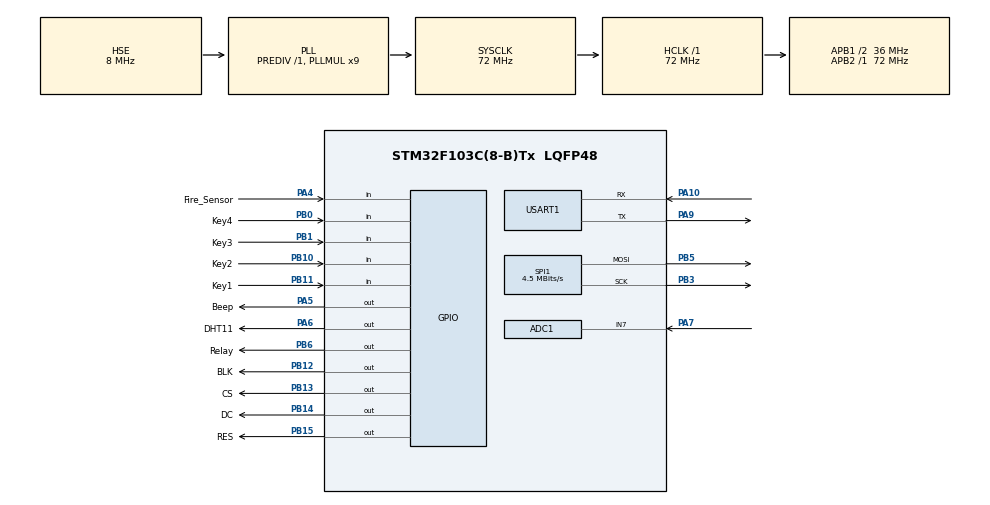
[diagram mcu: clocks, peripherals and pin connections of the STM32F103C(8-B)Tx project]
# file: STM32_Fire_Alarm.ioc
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ADC1.Channel-0\#ChannelRegularConversion=ADC_CHANNEL_7
ADC1.NbrOfConversionFlag=1
ADC1.Rank-0\#ChannelRegularConversion=1
ADC1.SamplingTime-0\#ChannelRegularConversion=ADC_SAMPLETIME_1CYCLE_5
ADC1.master=1
Dma.ADC1.3.Direction=DMA_PERIPH_TO_MEMORY
Dma.ADC1.3.Instance=DMA1_Channel1
Dma.ADC1.3.MemDataAlignment=DMA_MDATAALIGN_HALFWORD
Dma.ADC1.3.MemInc=DMA_MINC_ENABLE
Dma.ADC1.3.Mode=DMA_NORMAL
Dma.ADC1.3.PeriphDataAlignment=DMA_PDATAALIGN_HALFWORD
Dma.ADC1.3.PeriphInc=DMA_PINC_DISABLE
Dma.ADC1.3.Priority=DMA_PRIORITY_LOW
Dma.Request0=USART1_RX
Dma.Request1=USART1_TX
Dma.Request2=SPI1_TX
Dma.Request3=ADC1
Dma.SPI1_TX.2.Direction=DMA_MEMORY_TO_PERIPH
Dma.SPI1_TX.2.Instance=DMA1_Channel3
Dma.SPI1_TX.2.MemDataAlignment=DMA_MDATAALIGN_BYTE
Dma.SPI1_TX.2.MemInc=DMA_MINC_ENABLE
Dma.SPI1_TX.2.Mode=DMA_NORMAL
Dma.SPI1_TX.2.PeriphDataAlignment=DMA_PDATAALIGN_BYTE
Dma.SPI1_TX.2.PeriphInc=DMA_PINC_DISABLE
Dma.SPI1_TX.2.Priority=DMA_PRIORITY_LOW
Dma.USART1_RX.0.Direction=DMA_PERIPH_TO_MEMORY
Dma.USART1_RX.0.Instance=DMA1_Channel5
Dma.USART1_RX.0.MemDataAlignment=DMA_MDATAALIGN_BYTE
Dma.USART1_RX.0.MemInc=DMA_MINC_ENABLE
Dma.USART1_RX.0.Mode=DMA_NORMAL
Dma.USART1_RX.0.PeriphDataAlignment=DMA_PDATAALIGN_BYTE
Dma.USART1_RX.0.PeriphInc=DMA_PINC_DISABLE
Dma.USART1_RX.0.Priority=DMA_PRIORITY_LOW
Dma.USART1_TX.1.Direction=DMA_MEMORY_TO_PERIPH
Dma.USART1_TX.1.Instance=DMA1_Channel4
Dma.USART1_TX.1.MemDataAlignment=DMA_MDATAALIGN_BYTE
Dma.USART1_TX.1.MemInc=DMA_MINC_ENABLE
Dma.USART1_TX.1.Mode=DMA_NORMAL
Dma.USART1_TX.1.PeriphDataAlignment=DMA_PDATAALIGN_BYTE
Dma.USART1_TX.1.PeriphInc=DMA_PINC_DISABLE
Dma.USART1_TX.1.Priority=DMA_PRIORITY_LOW
Mcu.Family=STM32F1
Mcu.Name=STM32F103C(8-B)Tx
Mcu.Package=LQFP48
NVIC.DMA1_Channel1_IRQn=true\:0\:0\:false\:false\:true\:false\:true\:true
NVIC.DMA1_Channel3_IRQn=true\:0\:0\:false\:false\:true\:false\:true\:true
NVIC.DMA1_Channel4_IRQn=true\:0\:0\:false\:false\:true\:false\:true\:true
NVIC.DMA1_Channel5_IRQn=true\:0\:0\:false\:false\:true\:false\:true\:true
NVIC.PriorityGroup=NVIC_PRIORITYGROUP_4
NVIC.USART1_IRQn=true\:0\:0\:false\:false\:true\:true\:true\:true
PA10.Mode=Asynchronous
PA10.Signal=USART1_RX
PA13.Mode=Serial_Wire
PA13.Signal=SYS_JTMS-SWDIO
PA14.Mode=Serial_Wire
PA14.Signal=SYS_JTCK-SWCLK
PA4.GPIO_Label=Fire_Sensor
PA4.GPIO_PuPd=GPIO_PULLUP
PA4.Signal=GPIO_Input
PA5.GPIO_Label=Beep
PA5.Signal=GPIO_Output
PA6.GPIO_Label=DHT11
PA6.PinState=GPIO_PIN_SET
PA6.Signal=GPIO_Output
PA7.Signal=ADCx_IN7
PA9.Mode=Asynchronous
PA9.Signal=USART1_TX
PB0.GPIO_Label=Key4
PB0.GPIO_PuPd=GPIO_PULLUP
PB0.Signal=GPIO_Input
PB1.GPIO_Label=Key3
PB1.GPIO_PuPd=GPIO_PULLUP
PB1.Signal=GPIO_Input
PB10.GPIO_Label=Key2
PB10.GPIO_PuPd=GPIO_PULLUP
PB10.Signal=GPIO_Input
PB11.GPIO_Label=Key1
PB11.GPIO_PuPd=GPIO_PULLUP
PB11.Signal=GPIO_Input
PB12.GPIO_Label=BLK
PB12.GPIO_Speed=GPIO_SPEED_FREQ_HIGH
PB12.PinState=GPIO_PIN_SET
PB12.Signal=GPIO_Output
PB13.GPIO_Label=CS
PB13.GPIO_Speed=GPIO_SPEED_FREQ_HIGH
PB13.PinState=GPIO_PIN_SET
PB13.Signal=GPIO_Output
PB14.GPIO_Label=DC
PB14.GPIO_Speed=GPIO_SPEED_FREQ_HIGH
PB14.PinState=GPIO_PIN_SET
PB14.Signal=GPIO_Output
PB15.GPIO_Label=RES
PB15.GPIO_Speed=GPIO_SPEED_FREQ_HIGH
PB15.PinState=GPIO_PIN_SET
PB15.Signal=GPIO_Output
PB3.Mode=TX_Only_Simplex_Unidirect_Master
PB3.Signal=SPI1_SCK
PB5.Mode=TX_Only_Simplex_Unidirect_Master
PB5.Signal=SPI1_MOSI
PB6.GPIO_Label=Relay
PB6.Signal=GPIO_Output
PD0-OSC_IN.Mode=HSE-External-Oscillator
PD0-OSC_IN.Signal=RCC_OSC_IN
PD1-OSC_OUT.Mode=HSE-External-Oscillator
PD1-OSC_OUT.Signal=RCC_OSC_OUT
ProjectManager.HeapSize=0x200
ProjectManager.StackSize=0x400
ProjectManager.TargetToolchain=MDK-ARM V5.32
RCC.ADCPresc=RCC_ADCPCLK2_DIV6
RCC.AHBFreq_Value=72000000
RCC.APB1CLKDivider=RCC_HCLK_DIV2
RCC.APB1Freq_Value=36000000
RCC.APB1TimFreq_Value=72000000
RCC.APB2Freq_Value=72000000
RCC.APB2TimFreq_Value=72000000
RCC.HCLKFreq_Value=72000000
RCC.PLLMUL=RCC_PLL_MUL9
RCC.PLLSourceVirtual=RCC_PLLSOURCE_HSE
RCC.SYSCLKFreq_VALUE=72000000
RCC.SYSCLKSource=RCC_SYSCLKSOURCE_PLLCLK
RCC.USBFreq_Value=72000000
SH.ADCx_IN7.0=ADC1_IN7,IN7
SPI1.BaudRatePrescaler=SPI_BAUDRATEPRESCALER_16
SPI1.CalculateBaudRate=4.5 MBits/s
SPI1.Direction=SPI_DIRECTION_2LINES
SPI1.Mode=SPI_MODE_MASTER
SPI1.VirtualType=VM_MASTER
USART1.VirtualMode=VM_ASYNC
board=custom

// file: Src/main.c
/* USER CODE BEGIN Header */
/**
 ******************************************************************************
 * @file           : main.c
 * @brief          : Main program body
 ******************************************************************************
 * @attention
 *
 * Copyright (c) 2024 STMicroelectronics.
 * All rights reserved.
 *
 * This software is licensed under terms that can be found in the LICENSE file
 * in the root directory of this software component.
 * If no LICENSE file comes with this software, it is provided AS-IS.
 *
 ******************************************************************************
 */
/* USER CODE END Header */
#include "main.h"
#include "adc.h"
#include "dma.h"
#include "spi.h"
#include "usart.h"
#include "gpio.h"

/* USER CODE BEGIN Includes */
#include "sys.h"
#include "gui.h"
/* USER CODE END Includes */

/* USER CODE BEGIN PV */
uint8_t USART1_RX_BUF[USART_REC_LEN];
ESP_RX_STRUCT ESP_RXS;

short Fumes_Threshold_L;
short Fumes_Threshold_H;

/* USER CODE END PV */

void SystemClock_Config(void);

int main(void)
{

  /* MCU Configuration--------------------------------------------------------*/

  /* Reset of all peripherals, Initializes the Flash interface and the Systick. */
  HAL_Init();

  /* Configure the system clock */
  SystemClock_Config();

  /* Initialize all configured peripherals */
  MX_GPIO_Init();
  MX_DMA_Init();
  MX_ADC1_Init();
  MX_USART1_UART_Init();
  MX_SPI1_Init();

  /* Infinite loop */
  /* USER CODE BEGIN WHILE */
  _sys_Init();
  while (1)
  {
    _sys_Loop();
    // t_sys_Loop();
    /* USER CODE END WHILE */

  }
}

void SystemClock_Config(void)
{
  RCC_OscInitTypeDef RCC_OscInitStruct = {0};
  RCC_ClkInitTypeDef RCC_ClkInitStruct = {0};
  RCC_PeriphCLKInitTypeDef PeriphClkInit = {0};

  /** Initializes the RCC Oscillators according to the specified parameters
  * in the RCC_OscInitTypeDef structure.
  */
  RCC_OscInitStruct.OscillatorType = RCC_OSCILLATORTYPE_HSE;
  RCC_OscInitStruct.HSEState = RCC_HSE_ON;
  RCC_OscInitStruct.HSEPredivValue = RCC_HSE_PREDIV_DIV1;
  RCC_OscInitStruct.HSIState = RCC_HSI_ON;
  RCC_OscInitStruct.PLL.PLLState = RCC_PLL_ON;
  RCC_OscInitStruct.PLL.PLLSource = RCC_PLLSOURCE_HSE;
  RCC_OscInitStruct.PLL.PLLMUL = RCC_PLL_MUL9;
  if (HAL_RCC_OscConfig(&RCC_OscInitStruct) != HAL_OK)
  {
    Error_Handler();
  }

  /** Initializes the CPU, AHB and APB buses clocks
  */
  RCC_ClkInitStruct.ClockType = RCC_CLOCKTYPE_HCLK|RCC_CLOCKTYPE_SYSCLK
                              |RCC_CLOCKTYPE_PCLK1|RCC_CLOCKTYPE_PCLK2;
  RCC_ClkInitStruct.SYSCLKSource = RCC_SYSCLKSOURCE_PLLCLK;
  RCC_ClkInitStruct.AHBCLKDivider = RCC_SYSCLK_DIV1;
  RCC_ClkInitStruct.APB1CLKDivider = RCC_HCLK_DIV2;
  RCC_ClkInitStruct.APB2CLKDivider = RCC_HCLK_DIV1;

  if (HAL_RCC_ClockConfig(&RCC_ClkInitStruct, FLASH_LATENCY_2) != HAL_OK)
  {
    Error_Handler();
  }
  PeriphClkInit.PeriphClockSelection = RCC_PERIPHCLK_ADC;
  PeriphClkInit.AdcClockSelection = RCC_ADCPCLK2_DIV6;
  if (HAL_RCCEx_PeriphCLKConfig(&PeriphClkInit) != HAL_OK)
  {
    Error_Handler();
  }
}

void Error_Handler(void)
{
  __disable_irq();
  while (1)
  {
  }
}
